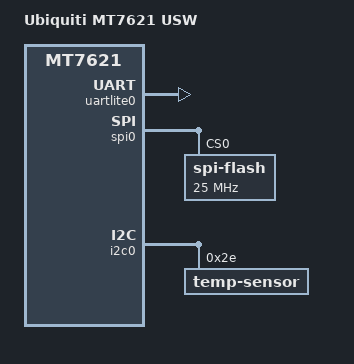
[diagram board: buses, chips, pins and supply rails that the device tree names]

/dts-v1/;
#include "mt7621.dtsi"

/ {
    model = "Ubiquiti MT7621 USW";
    compatible = "ubiquiti,mt7621-usw";

    aliases {
        spi0 = &spi0;
        serial0 = &uartlite0;
        i2c0 = &i2c0;
    };

    chosen {
        stdout-path = "serial0:115200n8";
    };

    signature {

        key-usw_mt7621 {
            rsa,r-squared = <0x993ffbd9 0x3242aac5 0x90935874 0x1670a815 0x2341ed87 0x9a1385f2 0xbb2b66f6 0x22d74384 0x9714e516 0xc595a43c 0x6bc94e1 0x259499d8 0xc1ef1ecb 0x763f200 0xffe5389e 0x84d7b32b 0x5d6a513a 0x17f58e87 0x9d8d3d3d 0xec324b02 0xc5ff2e1a 0x9a93b4fa 0x5c8c6d69 0x232c1fd8 0xf0c4d161 0x96653b56 0x2a0476f5 0x1b461a65 0x18f08922 0xf74b400f 0xa7f814f2 0x17cf4a09 0xc7dace47 0x87eef457 0x99c0ad85 0x21580996 0xf48b9f19 0x23a4ab53 0x63abd127 0x564e5df0 0x526caee5 0xd23bb132 0x5840f1ee 0x7579ebe6 0x11121ad8 0xec66519b 0x2dfdfb6e 0xd3f0a4c4 0x15438b7c 0xc43264e7 0x7c07c5fc 0x610350e7 0x7fe69e00 0x9a9ae204 0x30f2ef5 0x68f78dd0 0xa3cc8489 0x65a67fc4 0x760637cb 0x25993ac9 0xfcd064b 0x62a2b9c8 0x8d6c950e 0x6b8d89fa>;
            rsa,modulus = <0xab5b267f 0x4a4e4ad6 0x40646d73 0xbd16f6ce 0x4ea8baad 0xfce9ffcf 0xf1b07c57 0x37e18dc6 0x7873ae8c 0x9f183a82 0x986d33ae 0x30a36107 0xc6ec29e1 0xb5b542f2 0x7bd4f9a7 0x29019998 0x6b0469e8 0xccff7c92 0xbd2ab6bc 0x8082b0ca 0xcf290567 0x4f7294eb 0x8bd284e4 0x408c3cdc 0x8bdcfac 0x5bfc717 0x1077f3fc 0xea561d2e 0x8eaee6ec 0x23e2ce52 0xb138d77f 0x17bd38a2 0x769bb67f 0xf3edd7a1 0xe5ee57a4 0x22a9e4ac 0x1545cc1d 0x56703530 0x494974ca 0xdbf7299b 0x6006cfcd 0x351feb5 0x5a1336d1 0x1558c966 0xe1265b78 0x13e72170 0xd0fb77df 0x7e5d87b1 0xe30e60f5 0x242acae3 0x845acec5 0xedd981f3 0x485e017d 0x7f7a6f18 0xd2e54e42 0x4cf6c522 0xe3af8731 0x6731de3b 0x713ff6dd 0x42087d65 0xecd341c 0xeee65f9b 0xd8c2048a 0x9ab0ff23>;
            rsa,exponent = <0x0 0x10001>;
            rsa,n0-inverse = <0xdda7d775>;
            rsa,num-bits = <0x800>;
            required = "conf";
            algo = "sha1,rsa2048";
            key-name-hint = "usw_mt7621";
        };
    };
};

&uartlite0 {
    status = "okay";
};

&spi0 {
    spi-max-frequency = <25000000>;
    status = "okay";

    spi-flash@0 {
    #address-cells = <1>;
    #size-cells = <1>;
        compatible = "spi-flash";
        spi-max-frequency = <25000000>;
        reg = <0>;
    };
};

&i2c0 {
    status = "okay";

    temp-sensor@2e {
        reg = <0x2e>;
    };
};
